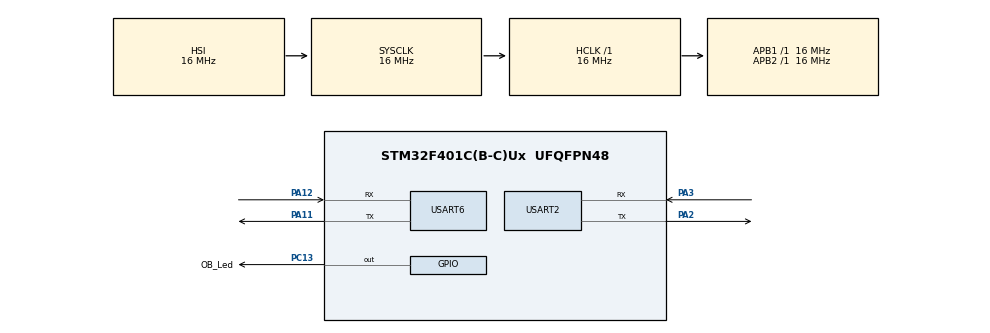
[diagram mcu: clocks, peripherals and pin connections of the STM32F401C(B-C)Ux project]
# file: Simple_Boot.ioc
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Mcu.Family=STM32F4
Mcu.Name=STM32F401C(B-C)Ux
Mcu.Package=UFQFPN48
NVIC.PriorityGroup=NVIC_PRIORITYGROUP_4
PA11.Mode=Asynchronous
PA11.Signal=USART6_TX
PA12.Mode=Asynchronous
PA12.Signal=USART6_RX
PA2.Mode=Asynchronous
PA2.Signal=USART2_TX
PA3.Mode=Asynchronous
PA3.Signal=USART2_RX
PC13-ANTI_TAMP.GPIO_Label=OB_Led
PC13-ANTI_TAMP.Signal=GPIO_Output
ProjectManager.HeapSize=0x200
ProjectManager.StackSize=0x400
ProjectManager.TargetToolchain=MDK-ARM V5.32
RCC.AHBFreq_Value=16000000
RCC.APB1Freq_Value=16000000
RCC.APB2Freq_Value=16000000
RCC.CortexFreq_Value=16000000
RCC.HSE_VALUE=25000000
RCC.HSI_VALUE=16000000
RCC.LSE_VALUE=32768
RCC.SYSCLKFreq_VALUE=16000000
RCC.VCOOutputFreq_Value=192000000
USART2.VirtualMode=VM_ASYNC
USART6.VirtualMode=VM_ASYNC
VP_CRC_VS_CRC.Mode=CRC_Activate
board=custom

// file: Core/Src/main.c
/* USER CODE BEGIN Header */
/**
  ******************************************************************************
  * @file           : main.c
  * @brief          : Main program body
  ******************************************************************************
  * @attention
  *
  * <h2><center>&copy; Copyright (c) 2024 STMicroelectronics.
  * All rights reserved.</center></h2>
  *
  * This software component is licensed by ST under BSD 3-Clause license,
  * the "License"; You may not use this file except in compliance with the
  * License. You may obtain a copy of the License at:
  *                        opensource.org/licenses/BSD-3-Clause
  *
  ******************************************************************************
  */
/* USER CODE END Header */
#include "main.h"
#include "crc.h"
#include "usart.h"
#include "gpio.h"

/* USER CODE BEGIN Includes */
#include "bootloader.h"
/* USER CODE END Includes */

/* USER CODE BEGIN PV */
BL_status status = BL_NOK;
uint8_t checkByte[1]={0};
uint8_t bytes[] = {0x4A, 0x16, 0xC0, 0x82, 0x08};
/* USER CODE END PV */

void SystemClock_Config(void);

int main(void)
{

  /* MCU Configuration--------------------------------------------------------*/

  /* Reset of all peripherals, Initializes the Flash interface and the Systick. */
  HAL_Init();

  /* Configure the system clock */
  SystemClock_Config();

  /* Initialize all configured peripherals */
  MX_GPIO_Init();
  MX_CRC_Init();
  MX_USART2_UART_Init();
  MX_USART6_UART_Init();

  /* Infinite loop */
  /* USER CODE BEGIN WHILE */
	BL_Print_Message("Bootloader started\r\n");
	HAL_GPIO_WritePin(GPIOC,GPIO_PIN_13,GPIO_PIN_SET); // means that bootloader is running
	/*HAL_FLASH_Unlock();

		for(uint16_t i = 0 ;i<5;i++){
			HAL_FLASH_Program(FLASH_TYPEPROGRAM_BYTE, 0x08008000+i, bytes[i]);
		}
		HAL_FLASH_Lock();*/
  //try_jump();
  while (1)
  {
    /* USER CODE END WHILE */

    /* USER CODE BEGIN 3 */

		  status = BL_UART_Featch_Host_Command();
	/*	HAL_StatusTypeDef hal_status = HAL_UART_Receive(&huart2,checkByte,1,HAL_MAX_DELAY);
		if(0x01 == (checkByte[0])){
			HAL_GPIO_WritePin(GPIOC,GPIO_PIN_13,GPIO_PIN_RESET); // turn the led off
		}*/

  }
  /* USER CODE END 3 */
}

void SystemClock_Config(void)
{
  RCC_OscInitTypeDef RCC_OscInitStruct = {0};
  RCC_ClkInitTypeDef RCC_ClkInitStruct = {0};

  /** Configure the main internal regulator output voltage
  */
  __HAL_RCC_PWR_CLK_ENABLE();
  __HAL_PWR_VOLTAGESCALING_CONFIG(PWR_REGULATOR_VOLTAGE_SCALE2);
  /** Initializes the RCC Oscillators according to the specified parameters
  * in the RCC_OscInitTypeDef structure.
  */
  RCC_OscInitStruct.OscillatorType = RCC_OSCILLATORTYPE_HSI;
  RCC_OscInitStruct.HSIState = RCC_HSI_ON;
  RCC_OscInitStruct.HSICalibrationValue = RCC_HSICALIBRATION_DEFAULT;
  RCC_OscInitStruct.PLL.PLLState = RCC_PLL_NONE;
  if (HAL_RCC_OscConfig(&RCC_OscInitStruct) != HAL_OK)
  {
    Error_Handler();
  }
  /** Initializes the CPU, AHB and APB buses clocks
  */
  RCC_ClkInitStruct.ClockType = RCC_CLOCKTYPE_HCLK|RCC_CLOCKTYPE_SYSCLK
                              |RCC_CLOCKTYPE_PCLK1|RCC_CLOCKTYPE_PCLK2;
  RCC_ClkInitStruct.SYSCLKSource = RCC_SYSCLKSOURCE_HSI;
  RCC_ClkInitStruct.AHBCLKDivider = RCC_SYSCLK_DIV1;
  RCC_ClkInitStruct.APB1CLKDivider = RCC_HCLK_DIV1;
  RCC_ClkInitStruct.APB2CLKDivider = RCC_HCLK_DIV1;

  if (HAL_RCC_ClockConfig(&RCC_ClkInitStruct, FLASH_LATENCY_0) != HAL_OK)
  {
    Error_Handler();
  }
}

void Error_Handler(void)
{
  __disable_irq();
  while (1)
  {
  }
}

/************************ (C) COPYRIGHT STMicroelectronics *****END OF FILE****/
